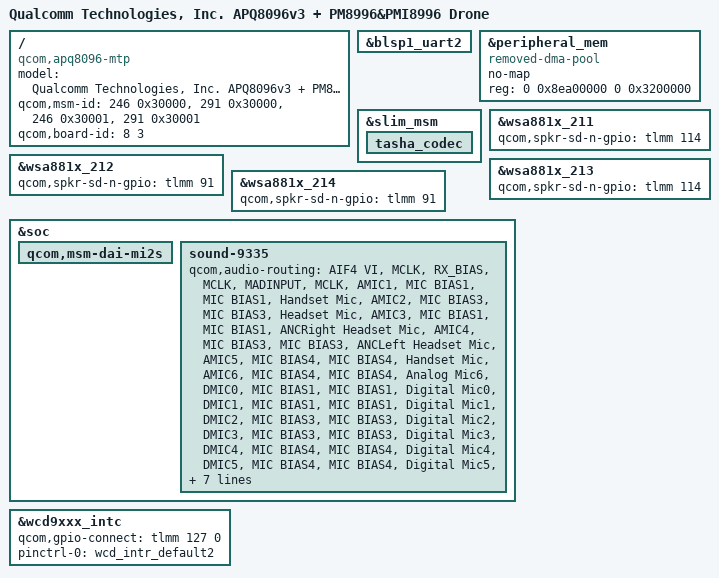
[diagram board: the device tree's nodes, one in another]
/* Copyright (c) 2016-2017, The Linux Foundation. All rights reserved.
 *
 * This program is free software; you can redistribute it and/or modify
 * it under the terms of the GNU General Public License version 2 and
 * only version 2 as published by the Free Software Foundation.
 *
 * This program is distributed in the hope that it will be useful,
 * but WITHOUT ANY WARRANTY; without even the implied warranty of
 * MERCHANTABILITY or FITNESS FOR A PARTICULAR PURPOSE.  See the
 * GNU General Public License for more details.
 */


/dts-v1/;

#include "apq8096-v3.dtsi"
#include "apq8096-drone.dtsi"
#include "msm8996-wsa881x.dtsi"

/ {
	model = "Qualcomm Technologies, Inc. APQ8096v3 + PM8996&PMI8996 Drone";
	compatible = "qcom,apq8096-mtp", "qcom,msm8996",
			"qcom,apq8096";
	qcom,msm-id = <246 0x30000>, <291 0x30000>,
			<246 0x30001>, <291 0x30001>;
	qcom,board-id = <8 3>;
};

&blsp1_uart2 {
	status = "ok";
};

&peripheral_mem {
	compatible = "removed-dma-pool";
	no-map;
	reg = <0 0x8ea00000 0 0x3200000>;
};

&slim_msm {
	status = "ok";
	tasha_codec {
		status = "ok";
	};
};

&wsa881x_211 {
	qcom,spkr-sd-n-gpio = <&tlmm 114 0>;
};

&wsa881x_212 {
	qcom,spkr-sd-n-gpio = <&tlmm 91 0>;
};

&wsa881x_213 {
	qcom,spkr-sd-n-gpio = <&tlmm 114 0>;
};

&wsa881x_214 {
	qcom,spkr-sd-n-gpio = <&tlmm 91 0>;
};


&soc {
	qcom,msm-dai-mi2s {
		status = "ok";
	};

	sound-9335 {
		status = "ok";

		qcom,audio-routing =
			"AIF4 VI", "MCLK",
			"RX_BIAS", "MCLK",
			"MADINPUT", "MCLK",
			"AMIC1", "MIC BIAS1",
			"MIC BIAS1", "Handset Mic",
			"AMIC2", "MIC BIAS3",
			"MIC BIAS3", "Headset Mic",
			"AMIC3", "MIC BIAS1",
			"MIC BIAS1", "ANCRight Headset Mic",
			"AMIC4", "MIC BIAS3",
			"MIC BIAS3", "ANCLeft Headset Mic",
			"AMIC5", "MIC BIAS4",
			"MIC BIAS4", "Handset Mic",
			"AMIC6", "MIC BIAS4",
			"MIC BIAS4", "Analog Mic6",
			"DMIC0", "MIC BIAS1",
			"MIC BIAS1", "Digital Mic0",
			"DMIC1", "MIC BIAS1",
			"MIC BIAS1", "Digital Mic1",
			"DMIC2", "MIC BIAS3",
			"MIC BIAS3", "Digital Mic2",
			"DMIC3", "MIC BIAS3",
			"MIC BIAS3", "Digital Mic3",
			"DMIC4", "MIC BIAS4",
			"MIC BIAS4", "Digital Mic4",
			"DMIC5", "MIC BIAS4",
			"MIC BIAS4", "Digital Mic5",
			"SpkrLeft IN", "SPK1 OUT",
			"SpkrRight IN", "SPK2 OUT";

		qcom,wsa-max-devs = <2>;
		qcom,wsa-devs = <&wsa881x_211>, <&wsa881x_212>,
				<&wsa881x_213>, <&wsa881x_214>;
		qcom,wsa-aux-dev-prefix = "SpkrLeft", "SpkrRight",
					  "SpkrLeft", "SpkrRight";
	};
};

&wcd9xxx_intc {
	qcom,gpio-connect = <&tlmm 127 0>;
	pinctrl-0 = <&wcd_intr_default2>;
};
